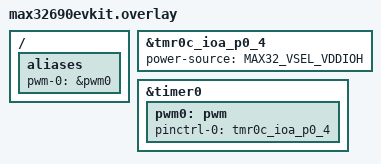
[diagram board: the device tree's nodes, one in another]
/*
 * Copyright (c) 2023 Analog Devices, Inc.
 *
 * SPDX-License-Identifier: Apache-2.0
 */

#include <zephyr/dt-bindings/gpio/adi-max32-gpio.h>

/ {
	aliases {
		pwm-0 = &pwm0;
	};
};

&tmr0c_ioa_p0_4 {
	power-source=<MAX32_VSEL_VDDIOH>;
};

&timer0 {
	status = "okay";
	pwm0: pwm {
		status = "okay";
		pinctrl-0 = <&tmr0c_ioa_p0_4>;
		pinctrl-names = "default";
	};
};
